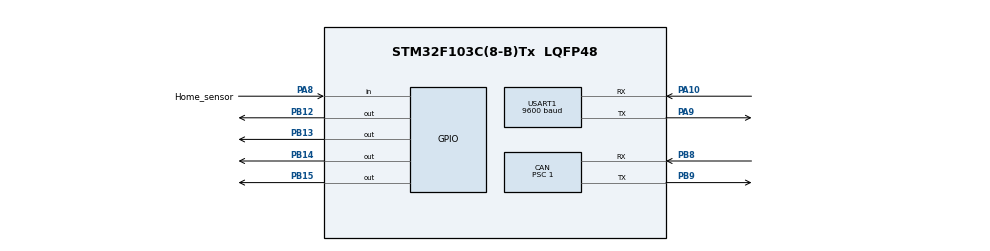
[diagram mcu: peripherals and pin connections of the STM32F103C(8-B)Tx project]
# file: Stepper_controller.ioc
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CAN.BS1=CAN_BS1_13TQ
CAN.BS2=CAN_BS2_2TQ
CAN.CalculateBaudRate=500000
CAN.CalculateTimeBit=2000
CAN.CalculateTimeQuantum=125.0
CAN.Prescaler=1
Mcu.Family=STM32F1
Mcu.Name=STM32F103C(8-B)Tx
Mcu.Package=LQFP48
NVIC.PriorityGroup=NVIC_PRIORITYGROUP_4
NVIC.TIM2_IRQn=true\:0\:0\:false\:false\:true\:true\:true\:true
NVIC.USART1_IRQn=true\:0\:0\:false\:false\:true\:true\:true\:true
NVIC.USB_LP_CAN1_RX0_IRQn=true\:0\:0\:false\:false\:true\:true\:true\:true
PA10.Mode=Asynchronous
PA10.Signal=USART1_RX
PA13.Mode=Serial_Wire
PA13.Signal=SYS_JTMS-SWDIO
PA14.Mode=Serial_Wire
PA14.Signal=SYS_JTCK-SWCLK
PA8.GPIO_Label=Home_sensor
PA8.GPIO_PuPd=GPIO_PULLUP
PA8.Signal=GPIO_Input
PA9.Mode=Asynchronous
PA9.Signal=USART1_TX
PB12.Signal=GPIO_Output
PB13.Signal=GPIO_Output
PB14.Signal=GPIO_Output
PB15.Signal=GPIO_Output
PB8.Mode=CAN_Activate
PB8.Signal=CAN_RX
PB9.Mode=CAN_Activate
PB9.Signal=CAN_TX
PD0-OSC_IN.Mode=HSE-External-Oscillator
PD0-OSC_IN.Signal=RCC_OSC_IN
PD1-OSC_OUT.Mode=HSE-External-Oscillator
PD1-OSC_OUT.Signal=RCC_OSC_OUT
ProjectManager.HeapSize=0x200
ProjectManager.StackSize=0x400
ProjectManager.TargetToolchain=CMake
RCC.APB1Freq_Value=8000000
RCC.APB2Freq_Value=8000000
TIM2.Period=2000
TIM2.Prescaler=8 - 1
USART1.BaudRate=9600
USART1.VirtualMode=VM_ASYNC
VP_TIM2_VS_ClockSourceINT.Mode=Internal
board=custom

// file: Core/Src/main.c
/* USER CODE BEGIN Header */
/**
  ******************************************************************************
  * @file           : main.c
  * @brief          : Main program body
  ******************************************************************************
  * @attention
  *
  * Copyright (c) 2026 STMicroelectronics.
  * All rights reserved.
  *
  * This software is licensed under terms that can be found in the LICENSE file
  * in the root directory of this software component.
  * If no LICENSE file comes with this software, it is provided AS-IS.
  *
  ******************************************************************************
  */
/* USER CODE END Header */
#include "main.h"
#include "can.h"
#include "tim.h"
#include "usart.h"
#include "gpio.h"

/* USER CODE BEGIN Includes */
#include "motion.h"
#include "cli.h"
#include "can_network.h"
#include <stdio.h>
/* USER CODE END Includes */

void SystemClock_Config(void);

int main(void)
{

  /* MCU Configuration--------------------------------------------------------*/

  /* Reset of all peripherals, Initializes the Flash interface and the Systick. */
  HAL_Init();

  /* Configure the system clock */
  SystemClock_Config();

  /* Initialize all configured peripherals */
  MX_GPIO_Init();
  MX_USART1_UART_Init();
  MX_TIM2_Init();
  MX_CAN_Init();

  /* USER CODE BEGIN 2 */
  printf("\r\n=== Stepper Motion Controller via CAN ===\r\n");
  printf("\r\n=== Type HOME for starting homing ===\r\n");

  Motion_Init();                  // Инициализация мотора
  CLI_Init();                     // Инициализация UART (для отладки)
  CAN_Network_Init();             // Инициализация CAN

  HAL_TIM_Base_Start_IT(&htim2);  // Запуск аппаратного таймера TIM2 в режиме прерываний

  /* USER CODE END 2 */

  /* Infinite loop */
  /* USER CODE BEGIN WHILE */
  while (1)
  {
      CAN_Network_Update();        // Передача к выполнению успешно принятой команды
      CAN_Network_UpdateStatus();  // Отправка циклической телеметрии и результата выполнения команды

    /* USER CODE END WHILE */

  }
}

void SystemClock_Config(void)
{
  RCC_OscInitTypeDef RCC_OscInitStruct = {0};
  RCC_ClkInitTypeDef RCC_ClkInitStruct = {0};

  /** Initializes the RCC Oscillators according to the specified parameters
  * in the RCC_OscInitTypeDef structure.
  */
  RCC_OscInitStruct.OscillatorType = RCC_OSCILLATORTYPE_HSI;
  RCC_OscInitStruct.HSIState = RCC_HSI_ON;
  RCC_OscInitStruct.HSICalibrationValue = RCC_HSICALIBRATION_DEFAULT;
  RCC_OscInitStruct.PLL.PLLState = RCC_PLL_NONE;
  if (HAL_RCC_OscConfig(&RCC_OscInitStruct) != HAL_OK)
  {
    Error_Handler();
  }

  /** Initializes the CPU, AHB and APB buses clocks
  */
  RCC_ClkInitStruct.ClockType = RCC_CLOCKTYPE_HCLK|RCC_CLOCKTYPE_SYSCLK
                              |RCC_CLOCKTYPE_PCLK1|RCC_CLOCKTYPE_PCLK2;
  RCC_ClkInitStruct.SYSCLKSource = RCC_SYSCLKSOURCE_HSI;
  RCC_ClkInitStruct.AHBCLKDivider = RCC_SYSCLK_DIV1;
  RCC_ClkInitStruct.APB1CLKDivider = RCC_HCLK_DIV1;
  RCC_ClkInitStruct.APB2CLKDivider = RCC_HCLK_DIV1;

  if (HAL_RCC_ClockConfig(&RCC_ClkInitStruct, FLASH_LATENCY_0) != HAL_OK)
  {
    Error_Handler();
  }
}

void Error_Handler(void)
{
  __disable_irq();
  while (1)
  {
  }
}
